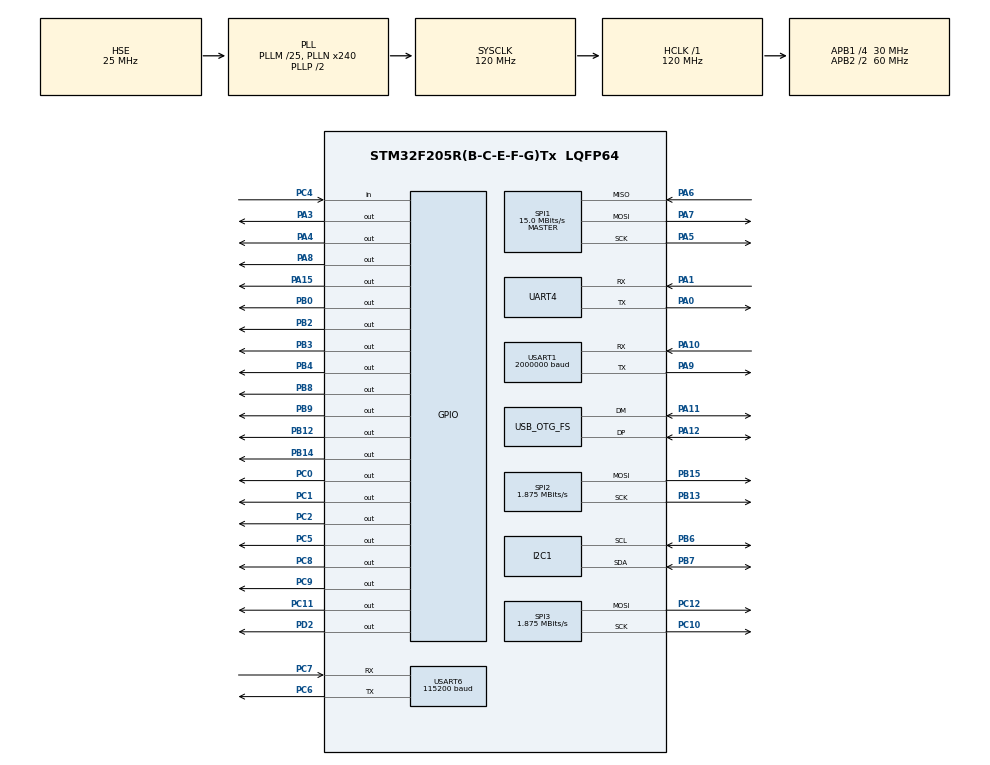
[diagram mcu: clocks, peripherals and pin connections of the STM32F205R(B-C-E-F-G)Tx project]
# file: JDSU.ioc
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Dma.Request0=USART1_TX
Dma.Request1=USART1_RX
Dma.Request2=TIM1_UP
Dma.Request3=USART6_TX
Dma.Request4=UART4_RX
Dma.Request5=UART4_TX
Dma.Request6=USART6_RX
Dma.TIM1_UP.2.Direction=DMA_MEMORY_TO_PERIPH
Dma.TIM1_UP.2.FIFOMode=DMA_FIFOMODE_DISABLE
Dma.TIM1_UP.2.Instance=DMA2_Stream5
Dma.TIM1_UP.2.MemDataAlignment=DMA_MDATAALIGN_WORD
Dma.TIM1_UP.2.MemInc=DMA_MINC_ENABLE
Dma.TIM1_UP.2.Mode=DMA_CIRCULAR
Dma.TIM1_UP.2.PeriphDataAlignment=DMA_PDATAALIGN_WORD
Dma.TIM1_UP.2.PeriphInc=DMA_PINC_DISABLE
Dma.TIM1_UP.2.Priority=DMA_PRIORITY_VERY_HIGH
Dma.UART4_RX.4.Direction=DMA_PERIPH_TO_MEMORY
Dma.UART4_RX.4.FIFOMode=DMA_FIFOMODE_DISABLE
Dma.UART4_RX.4.Instance=DMA1_Stream2
Dma.UART4_RX.4.MemDataAlignment=DMA_MDATAALIGN_BYTE
Dma.UART4_RX.4.MemInc=DMA_MINC_ENABLE
Dma.UART4_RX.4.Mode=DMA_NORMAL
Dma.UART4_RX.4.PeriphDataAlignment=DMA_PDATAALIGN_BYTE
Dma.UART4_RX.4.PeriphInc=DMA_PINC_DISABLE
Dma.UART4_RX.4.Priority=DMA_PRIORITY_LOW
Dma.UART4_TX.5.Direction=DMA_MEMORY_TO_PERIPH
Dma.UART4_TX.5.FIFOMode=DMA_FIFOMODE_DISABLE
Dma.UART4_TX.5.Instance=DMA1_Stream4
Dma.UART4_TX.5.MemDataAlignment=DMA_MDATAALIGN_BYTE
Dma.UART4_TX.5.MemInc=DMA_MINC_ENABLE
Dma.UART4_TX.5.Mode=DMA_NORMAL
Dma.UART4_TX.5.PeriphDataAlignment=DMA_PDATAALIGN_BYTE
Dma.UART4_TX.5.PeriphInc=DMA_PINC_DISABLE
Dma.UART4_TX.5.Priority=DMA_PRIORITY_LOW
Dma.USART1_RX.1.Direction=DMA_PERIPH_TO_MEMORY
Dma.USART1_RX.1.FIFOMode=DMA_FIFOMODE_DISABLE
Dma.USART1_RX.1.Instance=DMA2_Stream2
Dma.USART1_RX.1.MemDataAlignment=DMA_MDATAALIGN_BYTE
Dma.USART1_RX.1.MemInc=DMA_MINC_ENABLE
Dma.USART1_RX.1.Mode=DMA_NORMAL
Dma.USART1_RX.1.PeriphDataAlignment=DMA_PDATAALIGN_BYTE
Dma.USART1_RX.1.PeriphInc=DMA_PINC_DISABLE
Dma.USART1_RX.1.Priority=DMA_PRIORITY_HIGH
Dma.USART1_TX.0.Direction=DMA_MEMORY_TO_PERIPH
Dma.USART1_TX.0.FIFOMode=DMA_FIFOMODE_DISABLE
Dma.USART1_TX.0.Instance=DMA2_Stream7
Dma.USART1_TX.0.MemDataAlignment=DMA_MDATAALIGN_BYTE
Dma.USART1_TX.0.MemInc=DMA_MINC_ENABLE
Dma.USART1_TX.0.Mode=DMA_NORMAL
Dma.USART1_TX.0.PeriphDataAlignment=DMA_PDATAALIGN_BYTE
Dma.USART1_TX.0.PeriphInc=DMA_PINC_DISABLE
Dma.USART1_TX.0.Priority=DMA_PRIORITY_HIGH
Dma.USART6_RX.6.Direction=DMA_PERIPH_TO_MEMORY
Dma.USART6_RX.6.FIFOMode=DMA_FIFOMODE_DISABLE
Dma.USART6_RX.6.Instance=DMA2_Stream1
Dma.USART6_RX.6.MemDataAlignment=DMA_MDATAALIGN_BYTE
Dma.USART6_RX.6.MemInc=DMA_MINC_ENABLE
Dma.USART6_RX.6.Mode=DMA_NORMAL
Dma.USART6_RX.6.PeriphDataAlignment=DMA_PDATAALIGN_BYTE
Dma.USART6_RX.6.PeriphInc=DMA_PINC_DISABLE
Dma.USART6_RX.6.Priority=DMA_PRIORITY_MEDIUM
Dma.USART6_TX.3.Direction=DMA_MEMORY_TO_PERIPH
Dma.USART6_TX.3.FIFOMode=DMA_FIFOMODE_DISABLE
Dma.USART6_TX.3.Instance=DMA2_Stream6
Dma.USART6_TX.3.MemDataAlignment=DMA_MDATAALIGN_BYTE
Dma.USART6_TX.3.MemInc=DMA_MINC_ENABLE
Dma.USART6_TX.3.Mode=DMA_NORMAL
Dma.USART6_TX.3.PeriphDataAlignment=DMA_PDATAALIGN_BYTE
Dma.USART6_TX.3.PeriphInc=DMA_PINC_DISABLE
Dma.USART6_TX.3.Priority=DMA_PRIORITY_MEDIUM
I2C1.DutyCycle=I2C_DUTYCYCLE_16_9
I2C1.I2C_Mode=I2C_Fast
Mcu.Family=STM32F2
Mcu.Name=STM32F205R(B-C-E-F-G)Tx
Mcu.Package=LQFP64
NVIC.DMA1_Stream2_IRQn=true\:0\:0\:false\:false\:true\:false\:true\:true
NVIC.DMA1_Stream4_IRQn=true\:0\:0\:false\:false\:true\:false\:true\:true
NVIC.DMA2_Stream1_IRQn=true\:0\:0\:false\:false\:true\:false\:true\:true
NVIC.DMA2_Stream2_IRQn=true\:0\:0\:false\:false\:true\:false\:true\:true
NVIC.DMA2_Stream5_IRQn=true\:0\:0\:false\:false\:true\:false\:true\:true
NVIC.DMA2_Stream6_IRQn=true\:0\:0\:false\:false\:true\:false\:true\:true
NVIC.DMA2_Stream7_IRQn=true\:0\:0\:false\:false\:true\:false\:true\:true
NVIC.OTG_FS_IRQn=true\:0\:0\:false\:false\:true\:false\:true\:true
NVIC.PriorityGroup=NVIC_PRIORITYGROUP_2
NVIC.UART4_IRQn=true\:0\:0\:false\:false\:true\:true\:true\:true
NVIC.USART1_IRQn=true\:0\:0\:false\:false\:true\:false\:true\:true
NVIC.USART6_IRQn=true\:0\:0\:false\:false\:true\:true\:true\:true
PA0-WKUP.Mode=Asynchronous
PA0-WKUP.Signal=UART4_TX
PA1.Mode=Asynchronous
PA1.Signal=UART4_RX
PA10.GPIO_PuPd=GPIO_PULLUP
PA10.GPIO_Speed=GPIO_SPEED_FREQ_VERY_HIGH
PA10.Mode=Asynchronous
PA10.Signal=USART1_RX
PA11.Mode=Device_Only
PA11.Signal=USB_OTG_FS_DM
PA12.Mode=Device_Only
PA12.Signal=USB_OTG_FS_DP
PA15.GPIO_PuPd=GPIO_PULLUP
PA15.GPIO_Speed=GPIO_SPEED_FREQ_HIGH
PA15.PinState=GPIO_PIN_SET
PA15.Signal=GPIO_Output
PA3.GPIO_Speed=GPIO_SPEED_FREQ_HIGH
PA3.PinState=GPIO_PIN_SET
PA3.Signal=GPIO_Output
PA4.GPIO_PuPd=GPIO_PULLUP
PA4.GPIO_Speed=GPIO_SPEED_FREQ_HIGH
PA4.Signal=GPIO_Output
PA5.GPIO_PuPd=GPIO_PULLUP
PA5.GPIO_Speed=GPIO_SPEED_FREQ_VERY_HIGH
PA5.Mode=Full_Duplex_Master
PA5.Signal=SPI1_SCK
PA6.GPIO_PuPd=GPIO_PULLUP
PA6.Mode=Full_Duplex_Master
PA6.Signal=SPI1_MISO
PA7.GPIO_PuPd=GPIO_PULLUP
PA7.Mode=Full_Duplex_Master
PA7.Signal=SPI1_MOSI
PA8.GPIO_PuPd=GPIO_PULLUP
PA8.GPIO_Speed=GPIO_SPEED_FREQ_HIGH
PA8.PinState=GPIO_PIN_SET
PA8.Signal=GPIO_Output
PA9.GPIO_PuPd=GPIO_PULLUP
PA9.Mode=Asynchronous
PA9.Signal=USART1_TX
PB0.GPIO_Speed=GPIO_SPEED_FREQ_HIGH
PB0.PinState=GPIO_PIN_SET
PB0.Signal=GPIO_Output
PB12.GPIO_PuPd=GPIO_PULLUP
PB12.GPIO_Speed=GPIO_SPEED_FREQ_HIGH
PB12.PinState=GPIO_PIN_SET
PB12.Signal=GPIO_Output
PB13.GPIO_PuPd=GPIO_PULLUP
PB13.Mode=TX_Only_Simplex_Unidirect_Master
PB13.Signal=SPI2_SCK
PB14.GPIO_PuPd=GPIO_PULLUP
PB14.GPIO_Speed=GPIO_SPEED_FREQ_HIGH
PB14.PinState=GPIO_PIN_SET
PB14.Signal=GPIO_Output
PB15.GPIO_PuPd=GPIO_PULLUP
PB15.Mode=TX_Only_Simplex_Unidirect_Master
PB15.Signal=SPI2_MOSI
PB2.GPIO_Speed=GPIO_SPEED_FREQ_HIGH
PB2.PinState=GPIO_PIN_SET
PB2.Signal=GPIO_Output
PB3.GPIO_ModeDefaultOutputPP=GPIO_MODE_OUTPUT_PP
PB3.GPIO_PuPd=GPIO_PULLUP
PB3.GPIO_Speed=GPIO_SPEED_FREQ_HIGH
PB3.PinState=GPIO_PIN_SET
PB3.Signal=GPIO_Output
PB4.GPIO_ModeDefaultOutputPP=GPIO_MODE_OUTPUT_OD
PB4.GPIO_PuPd=GPIO_NOPULL
PB4.GPIO_Speed=GPIO_SPEED_FREQ_VERY_HIGH
PB4.PinState=GPIO_PIN_SET
PB4.Signal=GPIO_Output
PB6.Mode=I2C
PB6.Signal=I2C1_SCL
PB7.Mode=I2C
PB7.Signal=I2C1_SDA
PB8.GPIO_Speed=GPIO_SPEED_FREQ_HIGH
PB8.Signal=GPIO_Output
PB9.GPIO_Speed=GPIO_SPEED_FREQ_HIGH
PB9.Signal=GPIO_Output
PC0.GPIO_PuPd=GPIO_PULLUP
PC0.GPIO_Speed=GPIO_SPEED_FREQ_HIGH
PC0.Signal=GPIO_Output
PC1.GPIO_PuPd=GPIO_PULLUP
PC1.GPIO_Speed=GPIO_SPEED_FREQ_HIGH
PC1.Signal=GPIO_Output
PC10.GPIO_PuPd=GPIO_PULLUP
PC10.Mode=TX_Only_Simplex_Unidirect_Master
PC10.Signal=SPI3_SCK
PC11.GPIO_PuPd=GPIO_PULLUP
PC11.GPIO_Speed=GPIO_SPEED_FREQ_HIGH
PC11.PinState=GPIO_PIN_SET
PC11.Signal=GPIO_Output
PC12.GPIO_PuPd=GPIO_PULLUP
PC12.Mode=TX_Only_Simplex_Unidirect_Master
PC12.Signal=SPI3_MOSI
PC2.GPIO_Speed=GPIO_SPEED_FREQ_VERY_HIGH
PC2.Signal=GPIO_Output
PC4.GPIO_PuPd=GPIO_PULLUP
PC4.Signal=GPIO_Input
PC5.GPIO_Speed=GPIO_SPEED_FREQ_HIGH
PC5.PinState=GPIO_PIN_SET
PC5.Signal=GPIO_Output
PC6.Mode=Asynchronous
PC6.Signal=USART6_TX
PC7.Mode=Asynchronous
PC7.Signal=USART6_RX
PC8.GPIO_Speed=GPIO_SPEED_FREQ_LOW
PC8.PinState=GPIO_PIN_SET
PC8.Signal=GPIO_Output
PC9.GPIO_PuPd=GPIO_PULLUP
PC9.GPIO_Speed=GPIO_SPEED_FREQ_HIGH
PC9.Signal=GPIO_Output
PD2.GPIO_PuPd=GPIO_PULLUP
PD2.GPIO_Speed=GPIO_SPEED_FREQ_HIGH
PD2.Signal=GPIO_Output
PH0-OSC_IN.Mode=HSE-External-Clock-Source
PH0-OSC_IN.Signal=RCC_OSC_IN
PH1-OSC_OUT.Mode=HSE-External-Clock-Source
PH1-OSC_OUT.Signal=RCC_OSC_OUT
ProjectManager.HeapSize=0x400
ProjectManager.StackSize=0x1000
ProjectManager.TargetToolchain=MDK-ARM V5.32
RCC.48MHZClocksFreq_Value=48000000
RCC.AHBFreq_Value=120000000
RCC.APB1CLKDivider=RCC_HCLK_DIV4
RCC.APB1Freq_Value=30000000
RCC.APB1TimFreq_Value=60000000
RCC.APB2CLKDivider=RCC_HCLK_DIV2
RCC.APB2Freq_Value=60000000
RCC.APB2TimFreq_Value=120000000
RCC.CortexFreq_Value=120000000
RCC.HCLKFreq_Value=120000000
RCC.HSE_VALUE=25000000
RCC.HSI_VALUE=16000000
RCC.LSE_VALUE=32768
RCC.PLLM=25
RCC.PLLN=240
RCC.PLLQ=5
RCC.PLLSourceVirtual=RCC_PLLSOURCE_HSE
RCC.SYSCLKFreq_VALUE=120000000
RCC.SYSCLKSource=RCC_SYSCLKSOURCE_PLLCLK
RCC.VCOOutputFreq_Value=240000000
SPI1.BaudRatePrescaler=SPI_BAUDRATEPRESCALER_4
SPI1.CalculateBaudRate=15.0 MBits/s
SPI1.DataSize=SPI_DATASIZE_16BIT
SPI1.Direction=SPI_DIRECTION_2LINES
SPI1.Mode=SPI_MODE_MASTER
SPI1.VirtualType=VM_MASTER
SPI2.BaudRatePrescaler=SPI_BAUDRATEPRESCALER_16
SPI2.CLKPolarity=SPI_POLARITY_HIGH
SPI2.CalculateBaudRate=1.875 MBits/s
SPI2.DataSize=SPI_DATASIZE_16BIT
SPI2.Direction=SPI_DIRECTION_2LINES
SPI2.Mode=SPI_MODE_MASTER
SPI2.VirtualType=VM_MASTER
SPI3.BaudRatePrescaler=SPI_BAUDRATEPRESCALER_16
SPI3.CLKPolarity=SPI_POLARITY_HIGH
SPI3.CalculateBaudRate=1.875 MBits/s
SPI3.DataSize=SPI_DATASIZE_16BIT
SPI3.Direction=SPI_DIRECTION_2LINES
SPI3.Mode=SPI_MODE_MASTER
SPI3.VirtualType=VM_MASTER
TIM1.Period=15
TIM1.Prescaler=2
TIM1.TIM_MasterOutputTrigger=TIM_TRGO_UPDATE
UART4.VirtualMode=Asynchronous
USART1.BaudRate=2000000
USART1.VirtualMode=VM_ASYNC
USART6.BaudRate=115200
USART6.VirtualMode=VM_ASYNC
USB_DEVICE.CLASS_NAME_FS=CDC
USB_DEVICE.VirtualMode-CDC_FS=Cdc
USB_DEVICE.VirtualModeFS=Cdc_FS
USB_OTG_FS.VirtualMode=Device_Only
VP_TIM1_VS_ClockSourceINT.Mode=Internal
VP_USB_DEVICE_VS_USB_DEVICE_CDC_FS.Mode=CDC_FS
board=custom

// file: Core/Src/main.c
/* USER CODE BEGIN Header */
/**
  ******************************************************************************
  * @file           : main.c
  * @brief          : Main program body
  ******************************************************************************
  * @attention
  *
  * Copyright (c) 2026 STMicroelectronics.
  * All rights reserved.
  *
  * This software is licensed under terms that can be found in the LICENSE file
  * in the root directory of this software component.
  * If no LICENSE file comes with this software, it is provided AS-IS.
  *
  ******************************************************************************
  */
/* USER CODE END Header */
#include "main.h"
#include "usb_device.h"

/* USER CODE BEGIN Includes */
#include "usbd_cdc_if.h"
#include "wifi_transport.h"
#include "ota_update.h"

/* USER CODE END Includes */

I2C_HandleTypeDef hi2c1;

SPI_HandleTypeDef hspi1;
#if 0  /* Legacy MS5614T voltage DAC interfaces are intentionally disabled. */
SPI_HandleTypeDef hspi2;
SPI_HandleTypeDef hspi3;
#endif

TIM_HandleTypeDef htim1;
DMA_HandleTypeDef hdma_tim1_up;

UART_HandleTypeDef huart4;
UART_HandleTypeDef huart1;
UART_HandleTypeDef huart6;
DMA_HandleTypeDef hdma_uart4_rx;
DMA_HandleTypeDef hdma_uart4_tx;
DMA_HandleTypeDef hdma_usart1_tx;
DMA_HandleTypeDef hdma_usart1_rx;
DMA_HandleTypeDef hdma_usart6_tx;
DMA_HandleTypeDef hdma_usart6_rx;

/* USER CODE BEGIN PV */
uint8_t test = 0x21;
uint8_t workState = EXTRA_STATE;
#if 0  /* The DAC target is fixed to PI11210. */
uint8_t dacTarget = 0;
#endif

uint8_t txBuffer[PACK_SIZE] = {0};
uint8_t aTxBuffer[USART_TX_SIZE] = {0};
static uint8_t usbControlWasActive = 0U;
#if BW20_RECOVERY_BRIDGE
volatile uint32_t bw20BridgeBaud = 115200U;
static uint32_t bw20BridgeActiveBaud = 115200U;
static uint8_t bw20BridgeUsbTxBuffer[64];
static uint8_t bw20BridgeUsbTxPending = 0U;
#endif

/* USER CODE END PV */

void SystemClock_Config(void);
static void MX_GPIO_Init(void);
static void MX_DMA_Init(void);
static void MX_USART1_UART_Init(void);
#if 0  /* Legacy MS5614T voltage DAC interfaces are intentionally disabled. */
static void MX_SPI2_Init(void);
#endif
static void MX_SPI1_Init(void);
#if 0  /* Legacy MS5614T voltage DAC interfaces are intentionally disabled. */
static void MX_SPI3_Init(void);
#endif
static void MX_TIM1_Init(void);
static void MX_I2C1_Init(void);
static void MX_USART6_UART_Init(void);
static void MX_UART4_Init(void);
/* USER CODE BEGIN PFP */
static void FanPwmDmaError(DMA_HandleTypeDef *hdma);

/* USER CODE END PFP */

/* USER CODE BEGIN 0 */
extern USBD_HandleTypeDef hUsbDeviceFS;

/* USER CODE END 0 */

int main(void)
{

  /* MCU Configuration--------------------------------------------------------*/

  /* Reset of all peripherals, Initializes the Flash interface and the Systick. */
  HAL_Init();

  /* Configure the system clock */
  SystemClock_Config();

  /* Initialize all configured peripherals */
  MX_GPIO_Init();
  MX_DMA_Init();
  MX_USART1_UART_Init();
#if 0  /* Do not enable either legacy MS5614T voltage DAC. */
  MX_SPI2_Init();
#endif
  MX_SPI1_Init();
#if 0  /* Do not enable either legacy MS5614T voltage DAC. */
  MX_SPI3_Init();
#endif
  MX_TIM1_Init();
  MX_I2C1_Init();
  /* Probe the PI11210 with SOA gated and initialise its source code to zero.
     A failed probe is reported through status telemetry; no laser-current
     write is accepted until it recovers. */
  (void)PI11210_Init();
  /* Select the STM32 while its USB pull-up is still disabled.  Holding this
     state creates a real bus disconnect before the CDC device is started. */
  USB_ENABLE;
  HAL_Delay(500);
  MX_USB_DEVICE_Init();
  MX_USART6_UART_Init();
  MX_UART4_Init();
  /* USER CODE BEGIN 2 */
#if BW20_RECOVERY_BRIDGE
	/* Temporary transparent diagnostic path: PC COM6 <-> USART6 on PC6/PC7
	 * <-> BW20 AT UART.  No laser, ADC or MQTT activity runs here. */
	USB_ENABLE;
#else
	ADC_MANUAL_SPI_Init();

	aTxBuffer[0] = 0xFF;
	aTxBuffer[1] = 0xFF;
	HAL_UART_Receive_DMA(&huart1, uartFrame, USART_RX_SIZE);
	WifiTransport_Init();
	HAL_UARTEx_ReceiveToIdle_DMA(&huart6, atFrame, AT_RX_SIZE);
	__HAL_DMA_DISABLE_IT(&hdma_usart6_rx, DMA_IT_HT);

	/* Start fail-safe at full cooling until the first CRC-valid board
	 * temperature is available. */
	ThermalControl_Init();
	CH224Q_Init();
	hdma_tim1_up.XferErrorCallback = FanPwmDmaError;
	__HAL_TIM_ENABLE_DMA(&htim1, TIM_DMA_UPDATE);
	if(HAL_DMA_Start(&hdma_tim1_up, (uint32_t)pwm_buffer,
			(uint32_t)&(GPIOC->BSRR), ARR_1) != HAL_OK ||
		 HAL_TIM_Base_Start(&htim1) != HAL_OK)
	{
		FanPwmDmaError(&hdma_tim1_up);
	}

	HAL_GPIO_WritePin(CHOISE_0_A_PORT, CHOISE_0_A_PIN, (GPIO_PinState)CHOISE_0_A);
	HAL_GPIO_WritePin(CHOISE_0_B_PORT, CHOISE_0_B_PIN, (GPIO_PinState)CHOISE_0_B);
	HAL_GPIO_WritePin(CHOISE_1_A_PORT, CHOISE_1_A_PIN, (GPIO_PinState)CHOISE_1_A);
	HAL_GPIO_WritePin(CHOISE_1_B_PORT, CHOISE_1_B_PIN, (GPIO_PinState)CHOISE_1_B);

	USB_ENABLE;
//	UART_ENABLE;
#endif
  /* USER CODE END 2 */

  /* Infinite loop */
  /* USER CODE BEGIN WHILE */
  while (1)
  {
#if BW20_RECOVERY_BRIDGE
		USBD_CDC_HandleTypeDef *hcdc =
			(USBD_CDC_HandleTypeDef *)hUsbDeviceFS.pClassData;

		if(bw20BridgeBaud >= 9600U && bw20BridgeBaud <= 2000000U &&
		   bw20BridgeBaud != bw20BridgeActiveBaud)
		{
			HAL_UART_DeInit(&huart6);
			huart6.Init.BaudRate = bw20BridgeBaud;
			if(HAL_UART_Init(&huart6) == HAL_OK)
				bw20BridgeActiveBaud = bw20BridgeBaud;
		}

		if(bw20BridgeUsbTxPending && hcdc != NULL && hcdc->TxState == 0U)
			bw20BridgeUsbTxPending = 0U;

		if(!bw20BridgeUsbTxPending && hcdc != NULL && hcdc->TxState == 0U)
		{
			uint16_t length = 0U;
			while(length < sizeof(bw20BridgeUsbTxBuffer) &&
			      __HAL_UART_GET_FLAG(&huart6, UART_FLAG_RXNE))
			{
				bw20BridgeUsbTxBuffer[length++] =
					(uint8_t)(huart6.Instance->DR & 0xFFU);
			}
			if(length > 0U &&
			   CDC_Transmit_FS(bw20BridgeUsbTxBuffer, length) == USBD_OK)
				bw20BridgeUsbTxPending = 1U;
		}
		continue;
#else
		USB_ENABLE;
		/* Advance at most one <=980 us cooperative temperature primitive at a
		 * frame boundary.  CH224Q is hard-strapped on this PCB and its service is
		 * side-effect free; PI11210 protection remains live at every boundary. */
		ThermalControl_Process();
		CH224Q_Process();
		PI11210_Process();
		/* A physical USB removal has no opportunity to send the normal CDC
		 * DTR-close request.  The USB IRQ callbacks clear usbCdcHostOpen; consume
		 * that falling edge here so the abandoned local scan cannot continue and
		 * the LAN raw-byte client can take ownership immediately. */
		if(usbControlWasActive && !usbCdcHostOpen)
		{
			ApplyWorkState(EXTRA_STATE);
			(void)PI11210_SetSOAShutter(1U);
			ReceEndFlag = 0U;
			USB_ResetQueue();
		}
		usbControlWasActive = usbCdcHostOpen ? 1U : 0U;
		WifiTransport_SetLocalControlActive(usbCdcHostOpen);
		WifiTransport_Process();
		OtaUpdate_ProcessUsb();
		if(WifiTransport_IsOtaActive())
		{
			/* OTA owns the board exclusively.  Stop wavelength switching and
			 * close the SOA optical shutter before any flash programming. */
			if(workState != EXTRA_STATE) ApplyWorkState(EXTRA_STATE);
			(void)PI11210_SetSOAShutter(1U);
			ThermalControl_Process();
			CH224Q_Process();
			continue;
		}
		{
			uint8_t requestedMode;
			uint32_t requestId;
			/* EXTRA/MANUAL are idle safe points.  Active scan modes deliberately
			 * defer the same request to write_ms5614t_table's frame boundary. */
			if(WifiTransport_TakePendingMode(workState, 0U,
					&requestedMode, &requestId))
			{
				ApplyWorkState(requestedMode);
				WifiTransport_OnRemoteModeApplied(requestedMode, requestId);
			}
		}
		//workState = MANUAL_STATE;

		switch(workState)
		{
#if FBG_FEATURE_LEGACY_PEAK_MODES
			case TABLE_STATE:
			{
				write_ms5614t_table();
				break;
			}
			case PRECISION_TABLE_STATE:
			{
				write_ms5614t_table();
				break;
			}
#endif
			case MANUAL_STATE:
			{
				write_ms5614t_manual();
				break;
			}
			case EXTRA_STATE:
			{
				write_ms5614t_extra();
				break;
			}
		}
		WifiTransport_SetLocalControlActive(usbCdcHostOpen);
		WifiTransport_Process();
		ThermalControl_Process();
		CH224Q_Process();
#endif

//			if(at_transfer_complete){
//				at_transfer_complete = 0;
//
//				HAL_UART_Transmit_DMA(&huart6,
//															check,
//															sizeof(check)-1);
//			}
//
//			delay_ms(1000);

    /* USER CODE END WHILE */

  }
}

void SystemClock_Config(void)
{
  RCC_OscInitTypeDef RCC_OscInitStruct = {0};
  RCC_ClkInitTypeDef RCC_ClkInitStruct = {0};

  /** Initializes the RCC Oscillators according to the specified parameters
  * in the RCC_OscInitTypeDef structure.
  */
  RCC_OscInitStruct.OscillatorType = RCC_OSCILLATORTYPE_HSE;
  RCC_OscInitStruct.HSEState = RCC_HSE_BYPASS;
  RCC_OscInitStruct.PLL.PLLState = RCC_PLL_ON;
  RCC_OscInitStruct.PLL.PLLSource = RCC_PLLSOURCE_HSE;
  RCC_OscInitStruct.PLL.PLLM = 25;
  RCC_OscInitStruct.PLL.PLLN = 240;
  RCC_OscInitStruct.PLL.PLLP = RCC_PLLP_DIV2;
  RCC_OscInitStruct.PLL.PLLQ = 5;
  if (HAL_RCC_OscConfig(&RCC_OscInitStruct) != HAL_OK)
  {
    Error_Handler();
  }

  /** Initializes the CPU, AHB and APB buses clocks
  */
  RCC_ClkInitStruct.ClockType = RCC_CLOCKTYPE_HCLK|RCC_CLOCKTYPE_SYSCLK
                              |RCC_CLOCKTYPE_PCLK1|RCC_CLOCKTYPE_PCLK2;
  RCC_ClkInitStruct.SYSCLKSource = RCC_SYSCLKSOURCE_PLLCLK;
  RCC_ClkInitStruct.AHBCLKDivider = RCC_SYSCLK_DIV1;
  RCC_ClkInitStruct.APB1CLKDivider = RCC_HCLK_DIV4;
  RCC_ClkInitStruct.APB2CLKDivider = RCC_HCLK_DIV2;

  if (HAL_RCC_ClockConfig(&RCC_ClkInitStruct, FLASH_LATENCY_3) != HAL_OK)
  {
    Error_Handler();
  }
}

static void MX_I2C1_Init(void)
{

  hi2c1.Instance = I2C1;
  hi2c1.Init.ClockSpeed = 400000;
  hi2c1.Init.DutyCycle = I2C_DUTYCYCLE_16_9;
  hi2c1.Init.OwnAddress1 = 0;
  hi2c1.Init.AddressingMode = I2C_ADDRESSINGMODE_7BIT;
  hi2c1.Init.DualAddressMode = I2C_DUALADDRESS_DISABLE;
  hi2c1.Init.OwnAddress2 = 0;
  hi2c1.Init.GeneralCallMode = I2C_GENERALCALL_DISABLE;
  hi2c1.Init.NoStretchMode = I2C_NOSTRETCH_DISABLE;
  if (HAL_I2C_Init(&hi2c1) != HAL_OK)
  {
    Error_Handler();
  }

}

static void MX_SPI1_Init(void)
{

  /* SPI1 parameter configuration*/
  hspi1.Instance = SPI1;
  hspi1.Init.Mode = SPI_MODE_MASTER;
  hspi1.Init.Direction = SPI_DIRECTION_2LINES;
  hspi1.Init.DataSize = SPI_DATASIZE_16BIT;
  hspi1.Init.CLKPolarity = SPI_POLARITY_LOW;
  hspi1.Init.CLKPhase = SPI_PHASE_1EDGE;
  hspi1.Init.NSS = SPI_NSS_SOFT;
  hspi1.Init.BaudRatePrescaler = SPI_BAUDRATEPRESCALER_4;
  hspi1.Init.FirstBit = SPI_FIRSTBIT_MSB;
  hspi1.Init.TIMode = SPI_TIMODE_DISABLE;
  hspi1.Init.CRCCalculation = SPI_CRCCALCULATION_DISABLE;
  hspi1.Init.CRCPolynomial = 10;
  if (HAL_SPI_Init(&hspi1) != HAL_OK)
  {
    Error_Handler();
  }

}

#if 0  /* Legacy MS5614T voltage DAC initialization retained for reference. */
static void MX_SPI2_Init(void)
{

  /* SPI2 parameter configuration*/
  hspi2.Instance = SPI2;
  hspi2.Init.Mode = SPI_MODE_MASTER;
  hspi2.Init.Direction = SPI_DIRECTION_2LINES;
  hspi2.Init.DataSize = SPI_DATASIZE_16BIT;
  hspi2.Init.CLKPolarity = SPI_POLARITY_HIGH;
  hspi2.Init.CLKPhase = SPI_PHASE_1EDGE;
  hspi2.Init.NSS = SPI_NSS_SOFT;
  hspi2.Init.BaudRatePrescaler = SPI_BAUDRATEPRESCALER_16;
  hspi2.Init.FirstBit = SPI_FIRSTBIT_MSB;
  hspi2.Init.TIMode = SPI_TIMODE_DISABLE;
  hspi2.Init.CRCCalculation = SPI_CRCCALCULATION_DISABLE;
  hspi2.Init.CRCPolynomial = 10;
  if (HAL_SPI_Init(&hspi2) != HAL_OK)
  {
    Error_Handler();
  }

}

static void MX_SPI3_Init(void)
{

  /* SPI3 parameter configuration*/
  hspi3.Instance = SPI3;
  hspi3.Init.Mode = SPI_MODE_MASTER;
  hspi3.Init.Direction = SPI_DIRECTION_2LINES;
  hspi3.Init.DataSize = SPI_DATASIZE_16BIT;
  hspi3.Init.CLKPolarity = SPI_POLARITY_HIGH;
  hspi3.Init.CLKPhase = SPI_PHASE_1EDGE;
  hspi3.Init.NSS = SPI_NSS_SOFT;
  hspi3.Init.BaudRatePrescaler = SPI_BAUDRATEPRESCALER_16;
  hspi3.Init.FirstBit = SPI_FIRSTBIT_MSB;
  hspi3.Init.TIMode = SPI_TIMODE_DISABLE;
  hspi3.Init.CRCCalculation = SPI_CRCCALCULATION_DISABLE;
  hspi3.Init.CRCPolynomial = 10;
  if (HAL_SPI_Init(&hspi3) != HAL_OK)
  {
    Error_Handler();
  }

}

#endif

/* A fan waveform failure must not leave either cooling or optical power in an
 * indeterminate state.  This callback is also used for start-up failures. */
static void FanPwmDmaError(DMA_HandleTypeDef *hdma)
{
	(void)hdma;
	__HAL_TIM_DISABLE_DMA(&htim1, TIM_DMA_UPDATE);
	(void)HAL_TIM_Base_Stop(&htim1);
	ThermalControl_OnFanPwmFault();
	PI11210_EmergencyShutter();
}

static void MX_TIM1_Init(void)
{

  TIM_ClockConfigTypeDef sClockSourceConfig = {0};
  TIM_MasterConfigTypeDef sMasterConfig = {0};

  htim1.Instance = TIM1;
  htim1.Init.Prescaler = 2;
  htim1.Init.CounterMode = TIM_COUNTERMODE_UP;
  htim1.Init.Period = 15;
  htim1.Init.ClockDivision = TIM_CLOCKDIVISION_DIV1;
  htim1.Init.RepetitionCounter = 0;
  htim1.Init.AutoReloadPreload = TIM_AUTORELOAD_PRELOAD_DISABLE;
  if (HAL_TIM_Base_Init(&htim1) != HAL_OK)
  {
    Error_Handler();
  }
  sClockSourceConfig.ClockSource = TIM_CLOCKSOURCE_INTERNAL;
  if (HAL_TIM_ConfigClockSource(&htim1, &sClockSourceConfig) != HAL_OK)
  {
    Error_Handler();
  }
  sMasterConfig.MasterOutputTrigger = TIM_TRGO_UPDATE;
  sMasterConfig.MasterSlaveMode = TIM_MASTERSLAVEMODE_DISABLE;
  if (HAL_TIMEx_MasterConfigSynchronization(&htim1, &sMasterConfig) != HAL_OK)
  {
    Error_Handler();
  }

}

static void MX_UART4_Init(void)
{

  huart4.Instance = UART4;
  huart4.Init.BaudRate = 115200;
  huart4.Init.WordLength = UART_WORDLENGTH_8B;
  huart4.Init.StopBits = UART_STOPBITS_1;
  huart4.Init.Parity = UART_PARITY_NONE;
  huart4.Init.Mode = UART_MODE_TX_RX;
  huart4.Init.HwFlowCtl = UART_HWCONTROL_NONE;
  huart4.Init.OverSampling = UART_OVERSAMPLING_16;
  if (HAL_UART_Init(&huart4) != HAL_OK)
  {
    Error_Handler();
  }

}

static void MX_USART1_UART_Init(void)
{

  huart1.Instance = USART1;
  huart1.Init.BaudRate = 2000000;
  huart1.Init.WordLength = UART_WORDLENGTH_8B;
  huart1.Init.StopBits = UART_STOPBITS_1;
  huart1.Init.Parity = UART_PARITY_NONE;
  huart1.Init.Mode = UART_MODE_TX_RX;
  huart1.Init.HwFlowCtl = UART_HWCONTROL_NONE;
  huart1.Init.OverSampling = UART_OVERSAMPLING_16;
  if (HAL_UART_Init(&huart1) != HAL_OK)
  {
    Error_Handler();
  }

}

static void MX_USART6_UART_Init(void)
{

  huart6.Instance = USART6;
  huart6.Init.BaudRate = 115200;
  huart6.Init.WordLength = UART_WORDLENGTH_8B;
  huart6.Init.StopBits = UART_STOPBITS_1;
  huart6.Init.Parity = UART_PARITY_NONE;
  huart6.Init.Mode = UART_MODE_TX_RX;
  huart6.Init.HwFlowCtl = UART_HWCONTROL_NONE;
  huart6.Init.OverSampling = UART_OVERSAMPLING_16;
  if (HAL_UART_Init(&huart6) != HAL_OK)
  {
    Error_Handler();
  }

}

static void MX_DMA_Init(void)
{

  /* DMA controller clock enable */
  __HAL_RCC_DMA2_CLK_ENABLE();
  __HAL_RCC_DMA1_CLK_ENABLE();

  /* DMA interrupt init */
  /* DMA1_Stream2_IRQn interrupt configuration */
  HAL_NVIC_SetPriority(DMA1_Stream2_IRQn, 0, 0);
  HAL_NVIC_EnableIRQ(DMA1_Stream2_IRQn);
  /* DMA1_Stream4_IRQn interrupt configuration */
  HAL_NVIC_SetPriority(DMA1_Stream4_IRQn, 0, 0);
  HAL_NVIC_EnableIRQ(DMA1_Stream4_IRQn);
  /* DMA2_Stream1_IRQn interrupt configuration */
  HAL_NVIC_SetPriority(DMA2_Stream1_IRQn, 0, 0);
  HAL_NVIC_EnableIRQ(DMA2_Stream1_IRQn);
  /* DMA2_Stream2_IRQn interrupt configuration */
  HAL_NVIC_SetPriority(DMA2_Stream2_IRQn, 0, 0);
  HAL_NVIC_EnableIRQ(DMA2_Stream2_IRQn);
  /* DMA2_Stream5_IRQn interrupt configuration */
  HAL_NVIC_SetPriority(DMA2_Stream5_IRQn, 0, 0);
  HAL_NVIC_EnableIRQ(DMA2_Stream5_IRQn);
  /* DMA2_Stream6_IRQn interrupt configuration */
  HAL_NVIC_SetPriority(DMA2_Stream6_IRQn, 0, 0);
  HAL_NVIC_EnableIRQ(DMA2_Stream6_IRQn);
  /* DMA2_Stream7_IRQn interrupt configuration */
  HAL_NVIC_SetPriority(DMA2_Stream7_IRQn, 0, 0);
  HAL_NVIC_EnableIRQ(DMA2_Stream7_IRQn);

}

static void MX_GPIO_Init(void)
{
  GPIO_InitTypeDef GPIO_InitStruct = {0};

  /* GPIO Ports Clock Enable */
  __HAL_RCC_GPIOH_CLK_ENABLE();
  __HAL_RCC_GPIOC_CLK_ENABLE();
  __HAL_RCC_GPIOA_CLK_ENABLE();
  __HAL_RCC_GPIOB_CLK_ENABLE();
  __HAL_RCC_GPIOD_CLK_ENABLE();

  /*Configure GPIO pin Output Level */
  HAL_GPIO_WritePin(GPIOC, GPIO_PIN_0|GPIO_PIN_1|GPIO_PIN_2|GPIO_PIN_9, GPIO_PIN_RESET);

  /*Configure GPIO pin Output Level */
  HAL_GPIO_WritePin(GPIOA, GPIO_PIN_3|GPIO_PIN_15, GPIO_PIN_SET);

  /* Keep legacy DAC1 in hardware power-down. */
  HAL_GPIO_WritePin(GPIOA, GPIO_PIN_8, GPIO_PIN_RESET);

  /*Configure GPIO pin Output Level */
  /* TPC5121 CS is active low.  Keep it inactive whenever no 16-bit frame is
     being clocked; the ADC driver supplies the required high-time guard. */
  HAL_GPIO_WritePin(GPIOA, GPIO_PIN_4, GPIO_PIN_SET);

  /*Configure GPIO pin Output Level */
  HAL_GPIO_WritePin(GPIOC, GPIO_PIN_5|GPIO_PIN_8|GPIO_PIN_11, GPIO_PIN_SET);

  /*Configure GPIO pin Output Level */
  HAL_GPIO_WritePin(GPIOB, GPIO_PIN_0|GPIO_PIN_2|GPIO_PIN_12|GPIO_PIN_14
                          |GPIO_PIN_4, GPIO_PIN_SET);

  /* Keep legacy DAC2 in hardware power-down. */
  HAL_GPIO_WritePin(GPIOB, GPIO_PIN_3, GPIO_PIN_RESET);

  /*Configure GPIO pin Output Level */
  HAL_GPIO_WritePin(GPIOD, GPIO_PIN_2, GPIO_PIN_RESET);

  /*Configure GPIO pin Output Level */
  HAL_GPIO_WritePin(GPIOB, GPIO_PIN_8|GPIO_PIN_9, GPIO_PIN_RESET);

  /* PI11210 CLR is active high.  Keep SOA gated until its source code has
     explicitly been initialised; a power-on must not enable an old bias. */
  HAL_GPIO_WritePin(PI11210_CLR_PORT, PI11210_CLR_PIN, GPIO_PIN_SET);

  /*Configure GPIO pins : PC0 PC1 PC9 PC11 */
  GPIO_InitStruct.Pin = GPIO_PIN_0|GPIO_PIN_1|GPIO_PIN_9|GPIO_PIN_11;
  GPIO_InitStruct.Mode = GPIO_MODE_OUTPUT_PP;
  GPIO_InitStruct.Pull = GPIO_PULLUP;
  GPIO_InitStruct.Speed = GPIO_SPEED_FREQ_HIGH;
  HAL_GPIO_Init(GPIOC, &GPIO_InitStruct);

  /* Four-wire fan tachometer, normally two falling edges per revolution. */
  GPIO_InitStruct.Pin = GPIO_PIN_3;
  GPIO_InitStruct.Mode = GPIO_MODE_IT_FALLING;
  GPIO_InitStruct.Pull = GPIO_PULLUP;
  GPIO_InitStruct.Speed = GPIO_SPEED_FREQ_LOW;
  HAL_GPIO_Init(GPIOC, &GPIO_InitStruct);

  /*Configure GPIO pin : PC2 */
  GPIO_InitStruct.Pin = GPIO_PIN_2;
  GPIO_InitStruct.Mode = GPIO_MODE_OUTPUT_PP;
  GPIO_InitStruct.Pull = GPIO_NOPULL;
  GPIO_InitStruct.Speed = GPIO_SPEED_FREQ_VERY_HIGH;
  HAL_GPIO_Init(GPIOC, &GPIO_InitStruct);

  /*Configure GPIO pin : PA3 */
  GPIO_InitStruct.Pin = GPIO_PIN_3;
  GPIO_InitStruct.Mode = GPIO_MODE_OUTPUT_PP;
  GPIO_InitStruct.Pull = GPIO_NOPULL;
  GPIO_InitStruct.Speed = GPIO_SPEED_FREQ_HIGH;
  HAL_GPIO_Init(GPIOA, &GPIO_InitStruct);

  /*Configure GPIO pins : PA4 PA8 PA15 */
  GPIO_InitStruct.Pin = GPIO_PIN_4|GPIO_PIN_8|GPIO_PIN_15;
  GPIO_InitStruct.Mode = GPIO_MODE_OUTPUT_PP;
  GPIO_InitStruct.Pull = GPIO_PULLUP;
  GPIO_InitStruct.Speed = GPIO_SPEED_FREQ_HIGH;
  HAL_GPIO_Init(GPIOA, &GPIO_InitStruct);

  /*Configure GPIO pin : PC4 */
  GPIO_InitStruct.Pin = GPIO_PIN_4;
  GPIO_InitStruct.Mode = GPIO_MODE_INPUT;
  GPIO_InitStruct.Pull = GPIO_PULLUP;
  HAL_GPIO_Init(GPIOC, &GPIO_InitStruct);

  /*Configure GPIO pin : PC5 */
  GPIO_InitStruct.Pin = GPIO_PIN_5;
  GPIO_InitStruct.Mode = GPIO_MODE_OUTPUT_PP;
  GPIO_InitStruct.Pull = GPIO_NOPULL;
  GPIO_InitStruct.Speed = GPIO_SPEED_FREQ_HIGH;
  HAL_GPIO_Init(GPIOC, &GPIO_InitStruct);

  /*Configure GPIO pins : PB0 PB2 PB5 PB8 PB9 */
  GPIO_InitStruct.Pin = GPIO_PIN_0|GPIO_PIN_2|PI11210_CLR_PIN|GPIO_PIN_8|GPIO_PIN_9;
  GPIO_InitStruct.Mode = GPIO_MODE_OUTPUT_PP;
  GPIO_InitStruct.Pull = GPIO_NOPULL;
  GPIO_InitStruct.Speed = GPIO_SPEED_FREQ_HIGH;
  HAL_GPIO_Init(GPIOB, &GPIO_InitStruct);

  /*Configure GPIO pins : PB12 PB14 PB3 */
  GPIO_InitStruct.Pin = GPIO_PIN_12|GPIO_PIN_14|GPIO_PIN_3;
  GPIO_InitStruct.Mode = GPIO_MODE_OUTPUT_PP;
  GPIO_InitStruct.Pull = GPIO_PULLUP;
  GPIO_InitStruct.Speed = GPIO_SPEED_FREQ_HIGH;
  HAL_GPIO_Init(GPIOB, &GPIO_InitStruct);

  /*Configure GPIO pin : PC8 */
  GPIO_InitStruct.Pin = GPIO_PIN_8;
  GPIO_InitStruct.Mode = GPIO_MODE_OUTPUT_PP;
  GPIO_InitStruct.Pull = GPIO_NOPULL;
  GPIO_InitStruct.Speed = GPIO_SPEED_FREQ_LOW;
  HAL_GPIO_Init(GPIOC, &GPIO_InitStruct);

  /*Configure GPIO pin : PD2 */
  GPIO_InitStruct.Pin = GPIO_PIN_2;
  GPIO_InitStruct.Mode = GPIO_MODE_OUTPUT_PP;
  GPIO_InitStruct.Pull = GPIO_PULLUP;
  GPIO_InitStruct.Speed = GPIO_SPEED_FREQ_HIGH;
  HAL_GPIO_Init(GPIOD, &GPIO_InitStruct);

  /*Configure GPIO pin : PB4 */
  GPIO_InitStruct.Pin = GPIO_PIN_4;
  GPIO_InitStruct.Mode = GPIO_MODE_OUTPUT_OD;
  GPIO_InitStruct.Pull = GPIO_NOPULL;
  GPIO_InitStruct.Speed = GPIO_SPEED_FREQ_VERY_HIGH;
  HAL_GPIO_Init(GPIOB, &GPIO_InitStruct);

  /* USER CODE BEGIN MX_GPIO_Init_2 */

  HAL_NVIC_SetPriority(EXTI3_IRQn, 5, 0);
  HAL_NVIC_EnableIRQ(EXTI3_IRQn);

  /* USER CODE END MX_GPIO_Init_2 */
}

void Error_Handler(void)
{
  __disable_irq();
  while (1)
  {
  }
}
